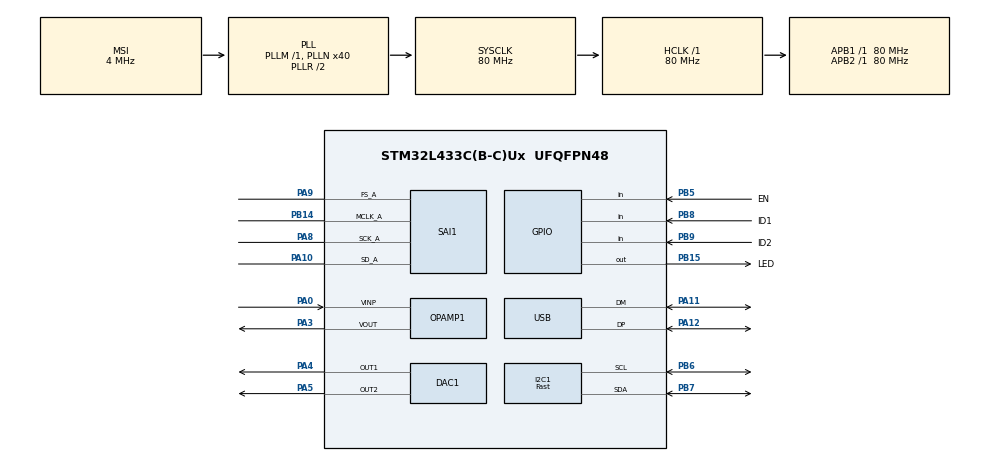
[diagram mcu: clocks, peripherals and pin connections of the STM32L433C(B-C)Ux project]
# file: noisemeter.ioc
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ADC1.Channel-1\#ChannelRegularConversion=ADC_CHANNEL_8
ADC1.ContinuousConvMode=DISABLE
ADC1.DMAContinuousRequests=ENABLE
ADC1.EOCSelection=ADC_EOC_SEQ_CONV
ADC1.ExternalTrigConv=ADC_EXTERNALTRIG_T15_TRGO
ADC1.NbrOfConversion=1
ADC1.NbrOfConversionFlag=1
ADC1.OffsetNumber-1\#ChannelRegularConversion=ADC_OFFSET_NONE
ADC1.Overrun=ADC_OVR_DATA_OVERWRITTEN
ADC1.OversamplingMode=ENABLE
ADC1.Rank-1\#ChannelRegularConversion=1
ADC1.Ratio=ADC_OVERSAMPLING_RATIO_16
ADC1.RightBitShift=ADC_RIGHTBITSHIFT_NONE
ADC1.SamplingTime-1\#ChannelRegularConversion=ADC_SAMPLETIME_47CYCLES_5
ADC1.master=1
DAC1.DAC_Channel-DAC_OUT2_ExtAndInt=DAC_CHANNEL_2
Dma.ADC1.0.Direction=DMA_PERIPH_TO_MEMORY
Dma.ADC1.0.Instance=DMA1_Channel1
Dma.ADC1.0.MemDataAlignment=DMA_MDATAALIGN_HALFWORD
Dma.ADC1.0.MemInc=DMA_MINC_ENABLE
Dma.ADC1.0.Mode=DMA_CIRCULAR
Dma.ADC1.0.PeriphDataAlignment=DMA_PDATAALIGN_HALFWORD
Dma.ADC1.0.PeriphInc=DMA_PINC_DISABLE
Dma.ADC1.0.Priority=DMA_PRIORITY_HIGH
Dma.Request0=ADC1
I2C1.I2C_Speed_Mode=I2C_Fast
I2C1.OwnAddress=0x10
I2C1.Timing=0x00702991
Mcu.Family=STM32L4
Mcu.Name=STM32L433C(B-C)Ux
Mcu.Package=UFQFPN48
NVIC.ADC1_IRQn=true\:0\:0\:false\:false\:true\:true\:true
NVIC.DMA1_Channel1_IRQn=true\:0\:0\:false\:false\:true\:false\:true
NVIC.I2C1_ER_IRQn=true\:0\:0\:false\:false\:true\:true\:true
NVIC.I2C1_EV_IRQn=true\:0\:0\:false\:false\:true\:true\:true
NVIC.PriorityGroup=NVIC_PRIORITYGROUP_4
NVIC.TIM1_BRK_TIM15_IRQn=true\:0\:0\:false\:false\:true\:true\:true
NVIC.USB_IRQn=true\:0\:0\:false\:false\:true\:false\:true
OPAMP1.PowerSupplyRange=OPAMP_POWERSUPPLY_HIGH
PA0.Mode=Follower
PA0.Signal=OPAMP1_VINP
PA1.Signal=OPAMP1_VINM
PA10.Mode=SAI_A_MasterWithClock
PA10.Signal=SAI1_SD_A
PA11.Mode=Device
PA11.Signal=USB_DM
PA12.Mode=Device
PA12.Signal=USB_DP
PA13\ (JTMS-SWDIO).Signal=SYS_JTMS-SWDIO
PA14\ (JTCK-SWCLK).Signal=SYS_JTCK-SWCLK
PA2.Signal=ADCx_IN7
PA3.Mode=Follower
PA3.Signal=OPAMP1_VOUT
PA4.Signal=COMP_DAC11_group
PA5.Signal=COMP_DAC12_group
PA8.Mode=SAI_A_MasterWithClock
PA8.Signal=SAI1_SCK_A
PA9.Mode=SAI_A_MasterWithClock
PA9.Signal=SAI1_FS_A
PB14.Mode=SAI_A_MasterWithClock
PB14.Signal=SAI1_MCLK_A
PB15.GPIO_Label=LED
PB15.Signal=GPIO_Output
PB3\ (JTDO-TRACESWO).Signal=SYS_JTDO-SWO
PB5.GPIO_Label=EN
PB5.Signal=GPIO_Input
PB6.GPIO_FM6=__NULL
PB6.Mode=I2C
PB6.Signal=I2C1_SCL
PB7.Mode=I2C
PB7.Signal=I2C1_SDA
PB8.GPIO_Label=ID1
PB8.Signal=GPIO_Input
PB9.GPIO_Label=ID2
PB9.Signal=GPIO_Input
PC14-OSC32_IN\ (PC14).Mode=LSE-External-Oscillator
PC14-OSC32_IN\ (PC14).Signal=RCC_OSC32_IN
PC15-OSC32_OUT\ (PC15).Mode=LSE-External-Oscillator
PC15-OSC32_OUT\ (PC15).Signal=RCC_OSC32_OUT
ProjectManager.HeapSize=0x200
ProjectManager.StackSize=0x400
ProjectManager.TargetToolchain=Makefile
RCC.ADCFreq_Value=48000000
RCC.AHBFreq_Value=80000000
RCC.APB1Freq_Value=80000000
RCC.APB1TimFreq_Value=80000000
RCC.APB2Freq_Value=80000000
RCC.APB2TimFreq_Value=80000000
RCC.CortexFreq_Value=80000000
RCC.HCLKFreq_Value=80000000
RCC.HSE_VALUE=8000000
RCC.HSI48_VALUE=48000000
RCC.HSI_VALUE=16000000
RCC.MSI_VALUE=4000000
RCC.PLLN=40
RCC.PLLSAI1N=24
RCC.SYSCLKFreq_VALUE=80000000
RCC.SYSCLKSource=RCC_SYSCLKSOURCE_PLLCLK
RCC.USBFreq_Value=48000000
RCC.VCOOutputFreq_Value=160000000
SAI1.AudioFrequency-SAI_A_MasterWithClock=SAI_AUDIO_FREQUENCY_48K
SAI1.DataSize-SAI_A_MasterWithClock=SAI_DATASIZE_32
SAI1.ErrorAudioFreq-SAI_A_MasterWithClock=-62.79 %
SAI1.FSOffset-SAI_A_MasterWithClock=SAI_FS_FIRSTBIT
SAI1.FrameLength-SAI_A_MasterWithClock=64
SAI1.Instance-SAI_A_MasterWithClock=SAI$Index_Block_A
SAI1.MClockEnable-SAI_A_MasterWithClock=SAI_MASTERCLOCK_ENABLE
SAI1.RealAudioFreq-SAI_A_MasterWithClock=17.857 KHz
SAI1.VirtualMode-SAI_A_MasterWithClock=VM_MASTER
SH.ADCx_IN7.0=ADC1_IN7
SH.COMP_DAC11_group.0=DAC1_OUT1,DAC_OUT1_ExtAndInt
SH.COMP_DAC12_group.0=DAC1_OUT2,DAC_OUT2_ExtAndInt
TIM15.AutoReloadPreload=TIM_AUTORELOAD_PRELOAD_DISABLE
TIM15.Period=1667
TIM15.TIM_MasterOutputTrigger=TIM_TRGO_UPDATE
USB_DEVICE.CLASS_NAME_FS=CDC
USB_DEVICE.MANUFACTURER_STRING=Press Every Key
USB_DEVICE.USBD_LPM_ENABLED=0
USB_DEVICE.USBD_SELF_POWERED=0
USB_DEVICE.VirtualMode=Cdc
USB_DEVICE.VirtualModeFS=Cdc_FS
VP_ADC1_OPAMP1_OUT.Mode=IN8-OPAMP1-Single-Ended
VP_RCC_USB.Mode=CRS SYNC Source USB
VP_SYS_V_PVD_IN.Mode=Mode_PVD_Int
VP_TIM15_VS_ClockSourceINT.Mode=Internal
VP_USB_DEVICE_VS_USB_DEVICE_CDC_FS.Mode=CDC_FS
board=custom

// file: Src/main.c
/* USER CODE BEGIN Header */
/**
  ******************************************************************************
  * @file           : main.c
  * @brief          : Main program body
  ******************************************************************************
  * @attention
  *
  * <h2><center>&copy; Copyright (c) 2019 STMicroelectronics.
  * All rights reserved.</center></h2>
  *
  * This software component is licensed by ST under Ultimate Liberty license
  * SLA0044, the "License"; You may not use this file except in compliance with
  * the License. You may obtain a copy of the License at:
  *                             www.st.com/SLA0044
  *
  ******************************************************************************
  */
/* USER CODE END Header */

#include "main.h"
#include "usb_device.h"

/* USER CODE BEGIN Includes */

#include "stm32l4xx_hal_adc.h"
#include "noisemeter.h"

/* USER CODE END Includes */

ADC_HandleTypeDef hadc1;
DMA_HandleTypeDef hdma_adc1;

DAC_HandleTypeDef hdac1;

I2C_HandleTypeDef hi2c1;

OPAMP_HandleTypeDef hopamp1;

SAI_HandleTypeDef hsai_BlockA1;

TIM_HandleTypeDef htim15;

void SystemClock_Config(void);
static void MX_GPIO_Init(void);
static void MX_DMA_Init(void);
static void MX_ADC1_Init(void);
static void MX_I2C1_Init(void);
static void MX_SAI1_Init(void);
static void MX_DAC1_Init(void);
static void MX_OPAMP1_Init(void);
static void MX_TIM15_Init(void);

/* USER CODE BEGIN 0 */

// void DMAComplete( DMA_HandleTypeDef *hdma) {
// //  LED_Toggle_Modulo();
// }

/* USER CODE END 0 */

int main(void)
{

  /* MCU Configuration--------------------------------------------------------*/

  /* Reset of all peripherals, Initializes the Flash interface and the Systick. */
  HAL_Init();

  /* Configure the system clock */
  SystemClock_Config();

  /* Initialize all configured peripherals */
  MX_GPIO_Init();
  MX_DMA_Init();
  MX_ADC1_Init();
  MX_I2C1_Init();
  MX_SAI1_Init();
  MX_USB_DEVICE_Init();
  MX_DAC1_Init();
  MX_OPAMP1_Init();
  MX_TIM15_Init();
  /* USER CODE BEGIN 2 */

  Noisemeter_Init();

  /* USER CODE END 2 */

  /* Infinite loop */
  while (1)
  {
    __WFI();
  }
}

void SystemClock_Config(void)
{
  RCC_OscInitTypeDef RCC_OscInitStruct = {0};
  RCC_ClkInitTypeDef RCC_ClkInitStruct = {0};
  RCC_PeriphCLKInitTypeDef PeriphClkInit = {0};
  RCC_CRSInitTypeDef RCC_CRSInitStruct = {0};

  /** Configure LSE Drive Capability
  */
  HAL_PWR_EnableBkUpAccess();
  __HAL_RCC_LSEDRIVE_CONFIG(RCC_LSEDRIVE_LOW);
  /** Initializes the CPU, AHB and APB busses clocks
  */
  RCC_OscInitStruct.OscillatorType = RCC_OSCILLATORTYPE_LSE|RCC_OSCILLATORTYPE_MSI;
  RCC_OscInitStruct.LSEState = RCC_LSE_ON;
  RCC_OscInitStruct.MSIState = RCC_MSI_ON;
  RCC_OscInitStruct.MSICalibrationValue = 0;
  RCC_OscInitStruct.MSIClockRange = RCC_MSIRANGE_6;
  RCC_OscInitStruct.PLL.PLLState = RCC_PLL_ON;
  RCC_OscInitStruct.PLL.PLLSource = RCC_PLLSOURCE_MSI;
  RCC_OscInitStruct.PLL.PLLM = 1;
  RCC_OscInitStruct.PLL.PLLN = 40;
  RCC_OscInitStruct.PLL.PLLP = RCC_PLLP_DIV7;
  RCC_OscInitStruct.PLL.PLLQ = RCC_PLLQ_DIV2;
  RCC_OscInitStruct.PLL.PLLR = RCC_PLLR_DIV2;
  if (HAL_RCC_OscConfig(&RCC_OscInitStruct) != HAL_OK)
  {
    Error_Handler();
  }
  /** Initializes the CPU, AHB and APB busses clocks
  */
  RCC_ClkInitStruct.ClockType = RCC_CLOCKTYPE_HCLK|RCC_CLOCKTYPE_SYSCLK
                              |RCC_CLOCKTYPE_PCLK1|RCC_CLOCKTYPE_PCLK2;
  RCC_ClkInitStruct.SYSCLKSource = RCC_SYSCLKSOURCE_PLLCLK;
  RCC_ClkInitStruct.AHBCLKDivider = RCC_SYSCLK_DIV1;
  RCC_ClkInitStruct.APB1CLKDivider = RCC_HCLK_DIV1;
  RCC_ClkInitStruct.APB2CLKDivider = RCC_HCLK_DIV1;

  if (HAL_RCC_ClockConfig(&RCC_ClkInitStruct, FLASH_LATENCY_4) != HAL_OK)
  {
    Error_Handler();
  }
  PeriphClkInit.PeriphClockSelection = RCC_PERIPHCLK_SAI1|RCC_PERIPHCLK_I2C1
                              |RCC_PERIPHCLK_USB|RCC_PERIPHCLK_ADC;
  PeriphClkInit.I2c1ClockSelection = RCC_I2C1CLKSOURCE_PCLK1;
  PeriphClkInit.Sai1ClockSelection = RCC_SAI1CLKSOURCE_PLLSAI1;
  PeriphClkInit.AdcClockSelection = RCC_ADCCLKSOURCE_PLLSAI1;
  PeriphClkInit.UsbClockSelection = RCC_USBCLKSOURCE_PLLSAI1;
  PeriphClkInit.PLLSAI1.PLLSAI1Source = RCC_PLLSOURCE_MSI;
  PeriphClkInit.PLLSAI1.PLLSAI1M = 1;
  PeriphClkInit.PLLSAI1.PLLSAI1N = 24;
  PeriphClkInit.PLLSAI1.PLLSAI1P = RCC_PLLP_DIV7;
  PeriphClkInit.PLLSAI1.PLLSAI1Q = RCC_PLLQ_DIV2;
  PeriphClkInit.PLLSAI1.PLLSAI1R = RCC_PLLR_DIV2;
  PeriphClkInit.PLLSAI1.PLLSAI1ClockOut = RCC_PLLSAI1_SAI1CLK|RCC_PLLSAI1_48M2CLK
                              |RCC_PLLSAI1_ADC1CLK;
  if (HAL_RCCEx_PeriphCLKConfig(&PeriphClkInit) != HAL_OK)
  {
    Error_Handler();
  }
  /** Configure the main internal regulator output voltage
  */
  if (HAL_PWREx_ControlVoltageScaling(PWR_REGULATOR_VOLTAGE_SCALE1) != HAL_OK)
  {
    Error_Handler();
  }
  /** Enable MSI Auto calibration
  */
  HAL_RCCEx_EnableMSIPLLMode();
  /** Enable the SYSCFG APB clock
  */
  __HAL_RCC_CRS_CLK_ENABLE();
  /** Configures CRS
  */
  RCC_CRSInitStruct.Prescaler = RCC_CRS_SYNC_DIV1;
  RCC_CRSInitStruct.Source = RCC_CRS_SYNC_SOURCE_USB;
  RCC_CRSInitStruct.Polarity = RCC_CRS_SYNC_POLARITY_RISING;
  RCC_CRSInitStruct.ReloadValue = __HAL_RCC_CRS_RELOADVALUE_CALCULATE(48000000,1000);
  RCC_CRSInitStruct.ErrorLimitValue = 34;
  RCC_CRSInitStruct.HSI48CalibrationValue = 32;

  HAL_RCCEx_CRSConfig(&RCC_CRSInitStruct);
}

static void MX_ADC1_Init(void)
{

  ADC_ChannelConfTypeDef sConfig = {0};

  /** Common config
  */
  hadc1.Instance = ADC1;
  hadc1.Init.ClockPrescaler = ADC_CLOCK_ASYNC_DIV1;
  hadc1.Init.Resolution = ADC_RESOLUTION_12B;
  hadc1.Init.DataAlign = ADC_DATAALIGN_RIGHT;
  hadc1.Init.ScanConvMode = ADC_SCAN_DISABLE;
  hadc1.Init.EOCSelection = ADC_EOC_SEQ_CONV;
  hadc1.Init.LowPowerAutoWait = DISABLE;
  hadc1.Init.ContinuousConvMode = DISABLE;
  hadc1.Init.NbrOfConversion = 1;
  hadc1.Init.DiscontinuousConvMode = DISABLE;
  hadc1.Init.ExternalTrigConv = ADC_EXTERNALTRIG_T15_TRGO;
  hadc1.Init.ExternalTrigConvEdge = ADC_EXTERNALTRIGCONVEDGE_RISING;
  hadc1.Init.DMAContinuousRequests = ENABLE;
  hadc1.Init.Overrun = ADC_OVR_DATA_OVERWRITTEN;
  hadc1.Init.OversamplingMode = ENABLE;
  hadc1.Init.Oversampling.Ratio = ADC_OVERSAMPLING_RATIO_16;
  hadc1.Init.Oversampling.RightBitShift = ADC_RIGHTBITSHIFT_NONE;
  hadc1.Init.Oversampling.TriggeredMode = ADC_TRIGGEREDMODE_SINGLE_TRIGGER;
  hadc1.Init.Oversampling.OversamplingStopReset = ADC_REGOVERSAMPLING_CONTINUED_MODE;
  if (HAL_ADC_Init(&hadc1) != HAL_OK)
  {
    Error_Handler();
  }
  /** Configure Regular Channel
  */
  sConfig.Channel = ADC_CHANNEL_8;
  sConfig.Rank = ADC_REGULAR_RANK_1;
  sConfig.SamplingTime = ADC_SAMPLETIME_47CYCLES_5;
  sConfig.SingleDiff = ADC_SINGLE_ENDED;
  sConfig.OffsetNumber = ADC_OFFSET_NONE;
  sConfig.Offset = 0;
  if (HAL_ADC_ConfigChannel(&hadc1, &sConfig) != HAL_OK)
  {
    Error_Handler();
  }

}

static void MX_DAC1_Init(void)
{

  DAC_ChannelConfTypeDef sConfig = {0};

  /** DAC Initialization
  */
  hdac1.Instance = DAC1;
  if (HAL_DAC_Init(&hdac1) != HAL_OK)
  {
    Error_Handler();
  }
  /** DAC channel OUT1 config
  */
  sConfig.DAC_SampleAndHold = DAC_SAMPLEANDHOLD_DISABLE;
  sConfig.DAC_Trigger = DAC_TRIGGER_NONE;
  sConfig.DAC_OutputBuffer = DAC_OUTPUTBUFFER_ENABLE;
  sConfig.DAC_ConnectOnChipPeripheral = DAC_CHIPCONNECT_ENABLE;
  sConfig.DAC_UserTrimming = DAC_TRIMMING_FACTORY;
  if (HAL_DAC_ConfigChannel(&hdac1, &sConfig, DAC_CHANNEL_1) != HAL_OK)
  {
    Error_Handler();
  }
  /** DAC channel OUT2 config
  */
  sConfig.DAC_ConnectOnChipPeripheral = DAC_CHIPCONNECT_ENABLE;
  if (HAL_DAC_ConfigChannel(&hdac1, &sConfig, DAC_CHANNEL_2) != HAL_OK)
  {
    Error_Handler();
  }

}

static void MX_I2C1_Init(void)
{

  hi2c1.Instance = I2C1;
  hi2c1.Init.Timing = 0x00702991;
  hi2c1.Init.OwnAddress1 = 32;
  hi2c1.Init.AddressingMode = I2C_ADDRESSINGMODE_7BIT;
  hi2c1.Init.DualAddressMode = I2C_DUALADDRESS_DISABLE;
  hi2c1.Init.OwnAddress2 = 0;
  hi2c1.Init.OwnAddress2Masks = I2C_OA2_NOMASK;
  hi2c1.Init.GeneralCallMode = I2C_GENERALCALL_DISABLE;
  hi2c1.Init.NoStretchMode = I2C_NOSTRETCH_DISABLE;
  if (HAL_I2C_Init(&hi2c1) != HAL_OK)
  {
    Error_Handler();
  }
  /** Configure Analogue filter
  */
  if (HAL_I2CEx_ConfigAnalogFilter(&hi2c1, I2C_ANALOGFILTER_ENABLE) != HAL_OK)
  {
    Error_Handler();
  }
  /** Configure Digital filter
  */
  if (HAL_I2CEx_ConfigDigitalFilter(&hi2c1, 0) != HAL_OK)
  {
    Error_Handler();
  }

}

static void MX_OPAMP1_Init(void)
{

  hopamp1.Instance = OPAMP1;
  hopamp1.Init.PowerSupplyRange = OPAMP_POWERSUPPLY_HIGH;
  hopamp1.Init.Mode = OPAMP_FOLLOWER_MODE;
  hopamp1.Init.NonInvertingInput = OPAMP_NONINVERTINGINPUT_IO0;
  hopamp1.Init.PowerMode = OPAMP_POWERMODE_NORMAL;
  hopamp1.Init.UserTrimming = OPAMP_TRIMMING_FACTORY;
  if (HAL_OPAMP_Init(&hopamp1) != HAL_OK)
  {
    Error_Handler();
  }

}

static void MX_SAI1_Init(void)
{

  hsai_BlockA1.Instance = SAI1_Block_A;
  hsai_BlockA1.Init.Protocol = SAI_FREE_PROTOCOL;
  hsai_BlockA1.Init.AudioMode = SAI_MODEMASTER_TX;
  hsai_BlockA1.Init.DataSize = SAI_DATASIZE_32;
  hsai_BlockA1.Init.FirstBit = SAI_FIRSTBIT_MSB;
  hsai_BlockA1.Init.ClockStrobing = SAI_CLOCKSTROBING_FALLINGEDGE;
  hsai_BlockA1.Init.Synchro = SAI_ASYNCHRONOUS;
  hsai_BlockA1.Init.OutputDrive = SAI_OUTPUTDRIVE_DISABLE;
  hsai_BlockA1.Init.NoDivider = SAI_MASTERDIVIDER_ENABLE;
  hsai_BlockA1.Init.FIFOThreshold = SAI_FIFOTHRESHOLD_EMPTY;
  hsai_BlockA1.Init.AudioFrequency = SAI_AUDIO_FREQUENCY_48K;
  hsai_BlockA1.Init.SynchroExt = SAI_SYNCEXT_DISABLE;
  hsai_BlockA1.Init.MonoStereoMode = SAI_STEREOMODE;
  hsai_BlockA1.Init.CompandingMode = SAI_NOCOMPANDING;
  hsai_BlockA1.Init.TriState = SAI_OUTPUT_NOTRELEASED;
  hsai_BlockA1.FrameInit.FrameLength = 64;
  hsai_BlockA1.FrameInit.ActiveFrameLength = 1;
  hsai_BlockA1.FrameInit.FSDefinition = SAI_FS_STARTFRAME;
  hsai_BlockA1.FrameInit.FSPolarity = SAI_FS_ACTIVE_LOW;
  hsai_BlockA1.FrameInit.FSOffset = SAI_FS_FIRSTBIT;
  hsai_BlockA1.SlotInit.FirstBitOffset = 0;
  hsai_BlockA1.SlotInit.SlotSize = SAI_SLOTSIZE_DATASIZE;
  hsai_BlockA1.SlotInit.SlotNumber = 1;
  hsai_BlockA1.SlotInit.SlotActive = 0x00000000;
  if (HAL_SAI_Init(&hsai_BlockA1) != HAL_OK)
  {
    Error_Handler();
  }

}

static void MX_TIM15_Init(void)
{

  TIM_ClockConfigTypeDef sClockSourceConfig = {0};
  TIM_MasterConfigTypeDef sMasterConfig = {0};

  htim15.Instance = TIM15;
  htim15.Init.Prescaler = 0;
  htim15.Init.CounterMode = TIM_COUNTERMODE_UP;
  htim15.Init.Period = 1667;
  htim15.Init.ClockDivision = TIM_CLOCKDIVISION_DIV1;
  htim15.Init.RepetitionCounter = 0;
  htim15.Init.AutoReloadPreload = TIM_AUTORELOAD_PRELOAD_DISABLE;
  if (HAL_TIM_Base_Init(&htim15) != HAL_OK)
  {
    Error_Handler();
  }
  sClockSourceConfig.ClockSource = TIM_CLOCKSOURCE_INTERNAL;
  if (HAL_TIM_ConfigClockSource(&htim15, &sClockSourceConfig) != HAL_OK)
  {
    Error_Handler();
  }
  sMasterConfig.MasterOutputTrigger = TIM_TRGO_UPDATE;
  sMasterConfig.MasterSlaveMode = TIM_MASTERSLAVEMODE_DISABLE;
  if (HAL_TIMEx_MasterConfigSynchronization(&htim15, &sMasterConfig) != HAL_OK)
  {
    Error_Handler();
  }

}

static void MX_DMA_Init(void)
{
  /* DMA controller clock enable */
  __HAL_RCC_DMA1_CLK_ENABLE();

  /* DMA interrupt init */
  /* DMA1_Channel1_IRQn interrupt configuration */
  HAL_NVIC_SetPriority(DMA1_Channel1_IRQn, 0, 0);
  HAL_NVIC_EnableIRQ(DMA1_Channel1_IRQn);

}

static void MX_GPIO_Init(void)
{
  GPIO_InitTypeDef GPIO_InitStruct = {0};

  /* GPIO Ports Clock Enable */
  __HAL_RCC_GPIOC_CLK_ENABLE();
  __HAL_RCC_GPIOH_CLK_ENABLE();
  __HAL_RCC_GPIOA_CLK_ENABLE();
  __HAL_RCC_GPIOB_CLK_ENABLE();

  /*Configure GPIO pin Output Level */
  HAL_GPIO_WritePin(LED_GPIO_Port, LED_Pin, GPIO_PIN_RESET);

  /*Configure GPIO pin : PC13 */
  GPIO_InitStruct.Pin = GPIO_PIN_13;
  GPIO_InitStruct.Mode = GPIO_MODE_ANALOG;
  GPIO_InitStruct.Pull = GPIO_NOPULL;
  HAL_GPIO_Init(GPIOC, &GPIO_InitStruct);

  /*Configure GPIO pins : PH0 PH1 PH3 */
  GPIO_InitStruct.Pin = GPIO_PIN_0|GPIO_PIN_1|GPIO_PIN_3;
  GPIO_InitStruct.Mode = GPIO_MODE_ANALOG;
  GPIO_InitStruct.Pull = GPIO_NOPULL;
  HAL_GPIO_Init(GPIOH, &GPIO_InitStruct);

  /*Configure GPIO pins : PA6 PA7 PA15 */
  GPIO_InitStruct.Pin = GPIO_PIN_6|GPIO_PIN_7|GPIO_PIN_15;
  GPIO_InitStruct.Mode = GPIO_MODE_ANALOG;
  GPIO_InitStruct.Pull = GPIO_NOPULL;
  HAL_GPIO_Init(GPIOA, &GPIO_InitStruct);

  /*Configure GPIO pins : PB0 PB1 PB2 PB10
                           PB11 PB12 PB13 PB4 */
  GPIO_InitStruct.Pin = GPIO_PIN_0|GPIO_PIN_1|GPIO_PIN_2|GPIO_PIN_10
                          |GPIO_PIN_11|GPIO_PIN_12|GPIO_PIN_13|GPIO_PIN_4;
  GPIO_InitStruct.Mode = GPIO_MODE_ANALOG;
  GPIO_InitStruct.Pull = GPIO_NOPULL;
  HAL_GPIO_Init(GPIOB, &GPIO_InitStruct);

  /*Configure GPIO pin : LED_Pin */
  GPIO_InitStruct.Pin = LED_Pin;
  GPIO_InitStruct.Mode = GPIO_MODE_OUTPUT_PP;
  GPIO_InitStruct.Pull = GPIO_NOPULL;
  GPIO_InitStruct.Speed = GPIO_SPEED_FREQ_LOW;
  HAL_GPIO_Init(LED_GPIO_Port, &GPIO_InitStruct);

  /*Configure GPIO pins : EN_Pin ID1_Pin ID2_Pin */
  GPIO_InitStruct.Pin = EN_Pin|ID1_Pin|ID2_Pin;
  GPIO_InitStruct.Mode = GPIO_MODE_INPUT;
  GPIO_InitStruct.Pull = GPIO_NOPULL;
  HAL_GPIO_Init(GPIOB, &GPIO_InitStruct);

}

void Error_Handler(void)
{
}

/************************ (C) COPYRIGHT STMicroelectronics *****END OF FILE****/
